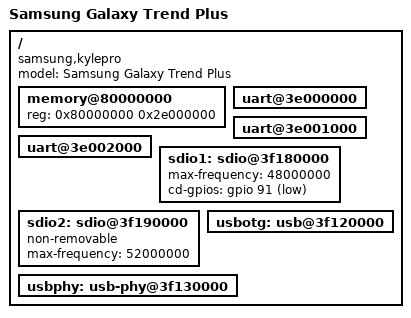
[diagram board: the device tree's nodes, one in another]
/*
 * Copyright (C) 2014 Broadcom Corporation
 *
 * This program is free software; you can redistribute it and/or
 * modify it under the terms of the GNU General Public License as
 * published by the Free Software Foundation version 2.
 *
 * This program is distributed "as is" WITHOUT ANY WARRANTY of any
 * kind, whether express or implied; without even the implied warranty
 * of MERCHANTABILITY or FITNESS FOR A PARTICULAR PURPOSE.  See the
 * GNU General Public License for more details.
 */

/dts-v1/;

#include <dt-bindings/gpio/gpio.h>

#include "bcm21664.dtsi"

/ {
	model = "Samsung Galaxy Trend Plus";
	compatible = "samsung,kylepro", "brcm,bcm21664";

	memory@80000000 {
		device_type = "memory";
		/*reg = <0x80000000 0x30000000>;*/ /* 768 MB */
		reg = <0x80000000 0x2e000000>; /* 736 MB */
	};

	uart@3e000000 {
		status = "okay";
	};

	uart@3e001000 {
		status = "okay";
	};

	uart@3e002000 {
		status = "okay";
	};

	sdio1: sdio@3f180000 {
		max-frequency = <48000000>;
		cd-gpios = <&gpio 91 GPIO_ACTIVE_LOW>;
		status = "okay";
	};

	sdio2: sdio@3f190000 {
		non-removable;
		max-frequency = <52000000>;
		status = "okay";
	};

	usbotg: usb@3f120000 {
		status = "okay";
	};

	usbphy: usb-phy@3f130000 {
		status = "okay";
	};
};
